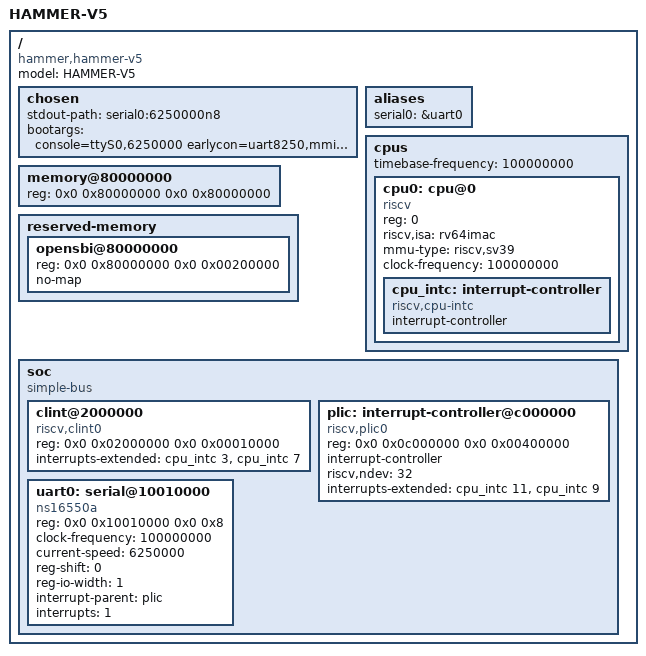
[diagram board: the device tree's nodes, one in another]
/dts-v1/;

/ {
    compatible = "hammer,hammer-v5";
    model = "HAMMER-V5";
    #address-cells = <2>;
    #size-cells = <2>;

    chosen {
        stdout-path = "serial0:6250000n8";
        bootargs = "console=ttyS0,6250000 earlycon=uart8250,mmio,0x10010000 mem=128M rdinit=/init";
    };

    aliases {
        serial0 = &uart0;
    };

    cpus {
        #address-cells = <1>;
        #size-cells = <0>;
        timebase-frequency = <100000000>;

        cpu0: cpu@0 {
            device_type = "cpu";
            compatible = "riscv";
            reg = <0>;
            status = "okay";
            riscv,isa = "rv64imac";
            mmu-type = "riscv,sv39";
            clock-frequency = <100000000>;
            cpu_intc: interrupt-controller {
                #interrupt-cells = <1>;
                interrupt-controller;
                compatible = "riscv,cpu-intc";
            };
        };
    };

    memory@80000000 {
        device_type = "memory";
        reg = <0x0 0x80000000 0x0 0x80000000>;
    };

    reserved-memory {
        #address-cells = <2>;
        #size-cells = <2>;
        ranges;
        opensbi@80000000 {
            reg = <0x0 0x80000000 0x0 0x00200000>;
            no-map;
        };
    };

    soc {
        compatible = "simple-bus";
        #address-cells = <2>;
        #size-cells = <2>;
        ranges;

        clint@2000000 {
            compatible = "riscv,clint0";
            reg = <0x0 0x02000000 0x0 0x00010000>;
            interrupts-extended = <&cpu_intc 3 &cpu_intc 7>;
        };

        plic: interrupt-controller@c000000 {
            compatible = "riscv,plic0";
            reg = <0x0 0x0c000000 0x0 0x00400000>;
            #interrupt-cells = <1>;
            interrupt-controller;
            riscv,ndev = <32>;
            interrupts-extended = <&cpu_intc 11 &cpu_intc 9>;
        };

        uart0: serial@10010000 {
            compatible = "ns16550a";
            reg = <0x0 0x10010000 0x0 0x8>;
            clock-frequency = <100000000>;
            current-speed = <6250000>;
            reg-shift = <0>;
            reg-io-width = <1>;
            interrupt-parent = <&plic>;
            interrupts = <1>;
        };
    };
};
